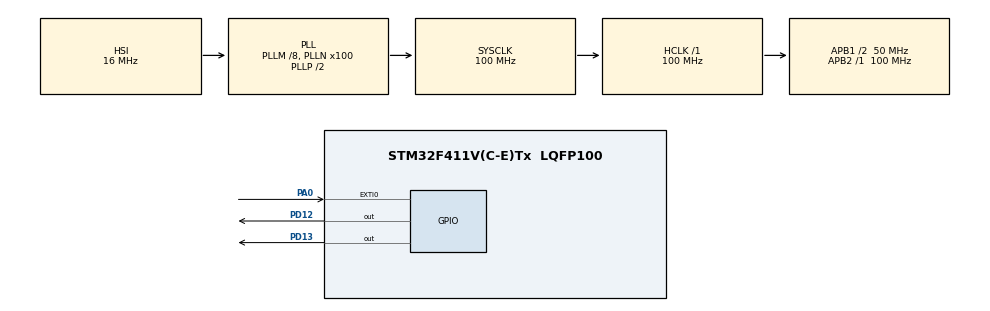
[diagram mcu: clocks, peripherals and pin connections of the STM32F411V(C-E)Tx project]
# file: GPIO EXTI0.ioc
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Mcu.Family=STM32F4
Mcu.Name=STM32F411V(C-E)Tx
Mcu.Package=LQFP100
NVIC.EXTI0_IRQn=true\:1\:0\:true\:false\:true\:true\:true
NVIC.PriorityGroup=NVIC_PRIORITYGROUP_4
PA0-WKUP.Signal=GPXTI0
PD12.Signal=GPIO_Output
PD13.Signal=GPIO_Output
ProjectManager.HeapSize=0x200
ProjectManager.StackSize=0x400
ProjectManager.TargetToolchain=MDK-ARM V5
RCC.48MHZClocksFreq_Value=50000000
RCC.AHBFreq_Value=100000000
RCC.APB1CLKDivider=RCC_HCLK_DIV2
RCC.APB1Freq_Value=50000000
RCC.APB1TimFreq_Value=100000000
RCC.APB2Freq_Value=100000000
RCC.APB2TimFreq_Value=100000000
RCC.CortexFreq_Value=100000000
RCC.HCLKFreq_Value=100000000
RCC.HSE_VALUE=25000000
RCC.HSI_VALUE=16000000
RCC.LSE_VALUE=32768
RCC.PLLM=8
RCC.PLLN=100
RCC.SYSCLKFreq_VALUE=100000000
RCC.SYSCLKSource=RCC_SYSCLKSOURCE_PLLCLK
RCC.VCOOutputFreq_Value=200000000
board=custom

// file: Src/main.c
/* USER CODE BEGIN Header */
/**
  ******************************************************************************
  * @file           : main.c
  * @brief          : Main program body
  ******************************************************************************
  * @attention
  *
  * <h2><center>&copy; Copyright (c) 2019 STMicroelectronics.
  * All rights reserved.</center></h2>
  *
  * This software component is licensed by ST under BSD 3-Clause license,
  * the "License"; You may not use this file except in compliance with the
  * License. You may obtain a copy of the License at:
  *                        opensource.org/licenses/BSD-3-Clause
  *
  ******************************************************************************
  */
/* USER CODE END Header */

#include "main.h"

void SystemClock_Config(void);
static void MX_GPIO_Init(void);

int main(void)
{

  /* MCU Configuration--------------------------------------------------------*/

  /* Reset of all peripherals, Initializes the Flash interface and the Systick. */
  HAL_Init();

  /* Configure the system clock */
  SystemClock_Config();

  /* Initialize all configured peripherals */
  MX_GPIO_Init();

  /* Infinite loop */
  while (1)
  {

    /* USER CODE BEGIN 3 */
		HAL_GPIO_TogglePin(GPIOD, GPIO_PIN_12);
		HAL_Delay(3000);
		HAL_SuspendTick();
		HAL_PWR_EnterSLEEPMode(PWR_LOWPOWERREGULATOR_ON, PWR_SLEEPENTRY_WFI);
		HAL_ResumeTick();
  }
  /* USER CODE END 3 */
}

void SystemClock_Config(void)
{
  RCC_OscInitTypeDef RCC_OscInitStruct = {0};
  RCC_ClkInitTypeDef RCC_ClkInitStruct = {0};

  /** Configure the main internal regulator output voltage
  */
  __HAL_RCC_PWR_CLK_ENABLE();
  __HAL_PWR_VOLTAGESCALING_CONFIG(PWR_REGULATOR_VOLTAGE_SCALE1);
  /** Initializes the CPU, AHB and APB busses clocks
  */
  RCC_OscInitStruct.OscillatorType = RCC_OSCILLATORTYPE_HSI;
  RCC_OscInitStruct.HSIState = RCC_HSI_ON;
  RCC_OscInitStruct.HSICalibrationValue = RCC_HSICALIBRATION_DEFAULT;
  RCC_OscInitStruct.PLL.PLLState = RCC_PLL_ON;
  RCC_OscInitStruct.PLL.PLLSource = RCC_PLLSOURCE_HSI;
  RCC_OscInitStruct.PLL.PLLM = 8;
  RCC_OscInitStruct.PLL.PLLN = 100;
  RCC_OscInitStruct.PLL.PLLP = RCC_PLLP_DIV2;
  RCC_OscInitStruct.PLL.PLLQ = 4;
  if (HAL_RCC_OscConfig(&RCC_OscInitStruct) != HAL_OK)
  {
    Error_Handler();
  }
  /** Initializes the CPU, AHB and APB busses clocks
  */
  RCC_ClkInitStruct.ClockType = RCC_CLOCKTYPE_HCLK|RCC_CLOCKTYPE_SYSCLK
                              |RCC_CLOCKTYPE_PCLK1|RCC_CLOCKTYPE_PCLK2;
  RCC_ClkInitStruct.SYSCLKSource = RCC_SYSCLKSOURCE_PLLCLK;
  RCC_ClkInitStruct.AHBCLKDivider = RCC_SYSCLK_DIV1;
  RCC_ClkInitStruct.APB1CLKDivider = RCC_HCLK_DIV2;
  RCC_ClkInitStruct.APB2CLKDivider = RCC_HCLK_DIV1;

  if (HAL_RCC_ClockConfig(&RCC_ClkInitStruct, FLASH_LATENCY_3) != HAL_OK)
  {
    Error_Handler();
  }
}

static void MX_GPIO_Init(void)
{
  GPIO_InitTypeDef GPIO_InitStruct = {0};

  /* GPIO Ports Clock Enable */
  __HAL_RCC_GPIOA_CLK_ENABLE();
  __HAL_RCC_GPIOD_CLK_ENABLE();

  /*Configure GPIO pin Output Level */
  HAL_GPIO_WritePin(GPIOD, GPIO_PIN_12|GPIO_PIN_13, GPIO_PIN_RESET);

  /*Configure GPIO pin : PA0 */
  GPIO_InitStruct.Pin = GPIO_PIN_0;
  GPIO_InitStruct.Mode = GPIO_MODE_IT_RISING;
  GPIO_InitStruct.Pull = GPIO_NOPULL;
  HAL_GPIO_Init(GPIOA, &GPIO_InitStruct);

  /*Configure GPIO pins : PD12 PD13 */
  GPIO_InitStruct.Pin = GPIO_PIN_12|GPIO_PIN_13;
  GPIO_InitStruct.Mode = GPIO_MODE_OUTPUT_PP;
  GPIO_InitStruct.Pull = GPIO_NOPULL;
  GPIO_InitStruct.Speed = GPIO_SPEED_FREQ_LOW;
  HAL_GPIO_Init(GPIOD, &GPIO_InitStruct);

  /* EXTI interrupt init*/
  HAL_NVIC_SetPriority(EXTI0_IRQn, 1, 0);
  HAL_NVIC_EnableIRQ(EXTI0_IRQn);

}

/* USER CODE BEGIN 4 */
void HAL_GPIO_EXTI_Callback(uint16_t GPIO_Pin)
{
	if(GPIO_Pin == GPIO_PIN_0)
	{
		HAL_GPIO_TogglePin(GPIOD, GPIO_PIN_13);
		//HAL_Delay(1000);
	}
}

/* USER CODE END 4 */

void Error_Handler(void)
{
}

/************************ (C) COPYRIGHT STMicroelectronics *****END OF FILE****/
